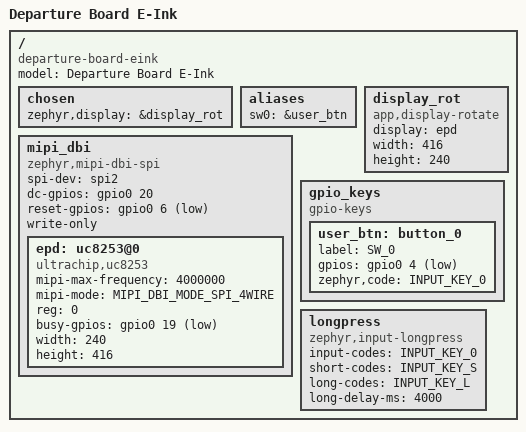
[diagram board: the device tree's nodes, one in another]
#include "../common/beetle_esp32c6_hpcore.dtsi"

/ {
	model = "Departure Board E-Ink";
	compatible = "departure-board-eink";

	chosen {
		zephyr,display = &display_rot;
	};

	aliases {
		sw0 = &user_btn;
	};

	mipi_dbi {
		compatible = "zephyr,mipi-dbi-spi";
		#address-cells = <1>;
		#size-cells = <0>;
		spi-dev = <&spi2>;
		dc-gpios = <&gpio0 20 GPIO_ACTIVE_HIGH>;
		reset-gpios = <&gpio0 6 GPIO_ACTIVE_LOW>;
		write-only;

		epd: uc8253@0 {
			compatible = "ultrachip,uc8253";
			mipi-max-frequency = <4000000>;
			mipi-mode = "MIPI_DBI_MODE_SPI_4WIRE";
			reg = <0>;
			busy-gpios = <&gpio0 19 GPIO_ACTIVE_LOW>;
			width = <240>;
			height = <416>;
		};
	};

	/* The panel scans portrait, the UI is landscape. See the binding for why neither the
	 * uc81xx driver nor LVGL can turn it themselves.
	 */
	display_rot: display_rot {
		compatible = "app,display-rotate";
		display = <&epd>;
		width = <416>;
		height = <240>;
	};

	gpio_keys {
		compatible = "gpio-keys";

		user_btn: button_0 {
			label = "SW_0";
			gpios = <&gpio0 4 (GPIO_PULL_UP | GPIO_ACTIVE_LOW)>;
			zephyr,code = <INPUT_KEY_0>;
		};
	};

	longpress {
		compatible = "zephyr,input-longpress";
		input-codes = <INPUT_KEY_0>;
		short-codes = <INPUT_KEY_S>;
		long-codes = <INPUT_KEY_L>;
		long-delay-ms = <4000>;
	};
};
